# ATSAMA5D31 register map
Vendor: Atmel; Series: SAMA5D3; File version: 20130221
Atmel ATSAMA5D31 device: ARM Cortex-A5 processor-based embedded MPU, 536MHz, Linux support, FPU, LCD controller, 10/100 Ethernet, security (refer to http://www.atmel.com/devices/SAMA5D31.aspx for more)
Registers are 32-bit, read-write, reset 0x0 unless marked. A register's access mark holds for its fields unless they carry their own. Offsets are from the block's base; lines under a group give offsets from that group; [hi:lo] are bit positions; {n}, {i} and the like mark numbered series; 'fields as' and 'values as' point back to an identical list; <NAME> marks a mode.

## Memory map
0x00400000 SMD size 0x100000 — Software Modem Device
0x00800000 AXIMX size 0x100000 — AXI Matrix
0xF0000000 HSMCI0 size 0x4000 — High Speed MultiMedia Card Interface 0
0xF0004000 SPI0 size 0x4000 — Serial Peripheral Interface 0
0xF0008000 SSC0 size 0x4000 — Synchronous Serial Controller 0
0xF0010000 TC0 size 0x4000 — Timer Counter 0
0xF0014000 TWI0 size 0x4000 — Two-wire Interface 0
0xF0018000 TWI1 size 0x4000 — Two-wire Interface 1
0xF001C000 USART0 size 0x4000 — Universal Synchronous Asynchronous Receiver Transmitter 0
0xF0020000 USART1 size 0x4000 — Universal Synchronous Asynchronous Receiver Transmitter 1
0xF0024000 UART0 size 0x4000 — Universal Asynchronous Receiver Transmitter 0
0xF002C000 PWM size 0x4000 — Pulse Width Modulation Controller
0xF0030000 LCDC size 0x4000 — LCD Controller
0xF0034000 ISI size 0x4000 — Image Sensor Interface
0xF0038000 SFR size 0x4000 — Special Function Registers
0xF8000000 HSMCI1 size 0x4000 — High Speed MultiMedia Card Interface 1
0xF8004000 HSMCI2 size 0x4000 — High Speed MultiMedia Card Interface 2
0xF8008000 SPI1 size 0x4000 — Serial Peripheral Interface 1
0xF800C000 SSC1 size 0x4000 — Synchronous Serial Controller 1
0xF8018000 ADC size 0x4000 — Analog-to-Digital Converter
0xF801C000 TWI2 size 0x4000 — Two-wire Interface 2
0xF8020000 USART2 size 0x4000 — Universal Synchronous Asynchronous Receiver Transmitter 2
0xF8024000 USART3 size 0x4000 — Universal Synchronous Asynchronous Receiver Transmitter 3
0xF8028000 UART1 size 0x4000 — Universal Asynchronous Receiver Transmitter 1
0xF802C000 EMAC size 0x4000 — Ethernet MAC 10/100
0xF8030000 UDPHS size 0x4000 — USB High Speed Device Port
0xF8040000 TRNG size 0x4000 — True Random Number Generator
0xFFFFE400 FUSE size 0x200 — Fuse Controller
0xFFFFE600 DMAC0 size 0x200 — DMA Controller 0
0xFFFFE800 DMAC1 size 0x200 — DMA Controller 1
0xFFFFEA00 MPDDRC size 0x200 — AHB Multi-port DDR-SDRAM Controller
0xFFFFEC00 MATRIX size 0x200 — AHB Bus Matrix
0xFFFFEE00 DBGU size 0x200 — Debug Unit
0xFFFFF000 AIC size 0x200 — Advanced Interrupt Controller
0xFFFFF200 PIOA size 0x200 — Parallel Input/Output Controller A
0xFFFFF400 PIOB size 0x200 — Parallel Input/Output Controller B
0xFFFFF600 PIOC size 0x200 — Parallel Input/Output Controller C
0xFFFFF800 PIOD size 0x200 — Parallel Input/Output Controller D
0xFFFFFA00 PIOE size 0x200 — Parallel Input/Output Controller E
0xFFFFFC00 PMC size 0x200 — Power Management Controller
0xFFFFFE00 RSTC size 0xC — Reset Controller
0xFFFFFE10 SHDWC size 0xC — Shutdown Controller
0xFFFFFE30 PIT size 0x10 — Periodic Interval Timer
0xFFFFFE40 WDT size 0xC — Watchdog Timer
0xFFFFFE50 SCKC size 0x4 — Slow Clock Controller
0xFFFFFE54 BSC size 0x4 — Boot Sequence Controller
0xFFFFFE60 GPBR size 0x10 — General Purpose Backup Register
0xFFFFFEB0 RTC size 0x30 — Real-time Clock

## Interrupts
0 FIQ (AIC)
1 PMC
2 DBGU
6 PIOA
7 PIOB
8 PIOC
9 PIOD
10 PIOE
11 SMD
12 USART0
13 USART1
14 USART2
15 USART3
16 UART0
17 UART1
18 TWI0
19 TWI1
20 TWI2
21 HSMCI0
22 HSMCI1
23 HSMCI2
24 SPI0
25 SPI1
26 TC0
27 TC1 (TC0)
28 PWM
29 ADC
30 DMAC0
31 DMAC1
33 UDPHS
35 EMAC
36 LCDC
37 ISI
38 SSC0
39 SSC1
45 TRNG
47 IRQ (AIC)
48 FUSE

## AXIMX — AXI Matrix
Base 0x00800000; register names take the prefix AXIMX_
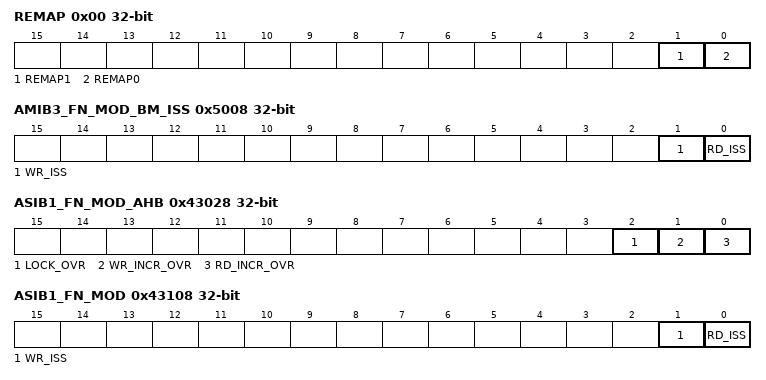
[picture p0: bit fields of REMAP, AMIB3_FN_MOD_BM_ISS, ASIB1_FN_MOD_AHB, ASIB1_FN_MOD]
0x00 REMAP wo
  [1] REMAP1 — Remap State 1
  [0] REMAP0 — Remap State 0
0x1FD0 PERIPH_ID4 ro reset 0x4 — Peripheral ID Register 4
  [7:0] ID — Peripheral ID
    1=Part Number; 4=4KB count, JEP106 continuation code; 179=JEP106[3:0, part number[11:8]; 182=Revision, JEP106 code flag, JEP106[6:4]
{0x1FC0+4i} PERIPH_ID{i} ro (i=5..7) — Peripheral ID Register {i}
  fields as PERIPH_ID4
0x1FE0 PERIPH_ID0 ro reset 0x1 — Peripheral ID Register 0
  fields as PERIPH_ID4
0x1FE4 PERIPH_ID1 ro reset 0xB3 — Peripheral ID Register 1
  fields as PERIPH_ID4
0x1FE8 PERIPH_ID2 ro reset 0x6B — Peripheral ID Register 2
  fields as PERIPH_ID4
0x1FEC PERIPH_ID3 ro — Peripheral ID Register 3
  fields as PERIPH_ID4
{0x1FF0+4i} COMP_ID[{i}] (i=0..3) ro reset not defined — Component ID Register
  [7:0] ID — Component ID
0x5008 AMIB3_FN_MOD_BM_ISS — AMIB3 Bus Matrix Functionality Modification Register
  [1] WR_ISS — Write Issuing
  [0] RD_ISS — Read Issuing
0x5024 AMIB3_FN_MOD2 — AMIB3 Bypass Merge
  [0] BP_MRG — Bypass Merge
0x42100 ASIB0_READ_QOS — ASIB0 Read Channel QoS Register
  [3:0] RD_QOS — Read QoS
0x42104 ASIB0_WRITE_QOS — ASIB0 Write Channel QoS Register
  [3:0] WR_QOS — Write QoS
0x43028 ASIB1_FN_MOD_AHB — ASIB1 AHB Functionality Modification Register
  [2] LOCK_OVR — Lock Override
  [1] WR_INCR_OVR — Write INCR override
  [0] RD_INCR_OVR — Read INCR Override
0x43100 ASIB1_READ_QOS — ASIB1 Read Channel QoS Register
  [3:0] RD_QOS — Read QoS
0x43104 ASIB1_WRITE_QOS — ASIB1 Write Channel QoS Register
  [3:0] WR_QOS — Write QoS
0x43108 ASIB1_FN_MOD — ASIB1 Issuing Functionality Modification Register
  [1] WR_ISS — Write Issuing
  [0] RD_ISS — Read Issuing

## Notices in the file
SAM Software Package License
Copyright (c) 2013, Atmel Corporation
All rights reserved.
Redistribution and use in source and binary forms, with or without
modification, are permitted provided that the following condition is met:
- Redistributions of source code must retain the above copyright notice,
this list of conditions and the disclaimer below.
Atmel's name may not be used to endorse or promote products derived from
this software without specific prior written permission.
DISCLAIMER:  THIS SOFTWARE IS PROVIDED BY ATMEL "AS IS" AND ANY EXPRESS OR
IMPLIED WARRANTIES, INCLUDING, BUT NOT LIMITED TO, THE IMPLIED WARRANTIES OF
MERCHANTABILITY, FITNESS FOR A PARTICULAR PURPOSE AND NON-INFRINGEMENT ARE
DISCLAIMED. IN NO EVENT SHALL ATMEL BE LIABLE FOR ANY DIRECT, INDIRECT,
INCIDENTAL, SPECIAL, EXEMPLARY, OR CONSEQUENTIAL DAMAGES (INCLUDING, BUT NOT
LIMITED TO, PROCUREMENT OF SUBSTITUTE GOODS OR SERVICES; LOSS OF USE, DATA,
OR PROFITS; OR BUSINESS INTERRUPTION) HOWEVER CAUSED AND ON ANY THEORY OF
LIABILITY, WHETHER IN CONTRACT, STRICT LIABILITY, OR TORT (INCLUDING
NEGLIGENCE OR OTHERWISE) ARISING IN ANY WAY OUT OF THE USE OF THIS SOFTWARE,
EVEN IF ADVISED OF THE POSSIBILITY OF SUCH DAMAGE.
